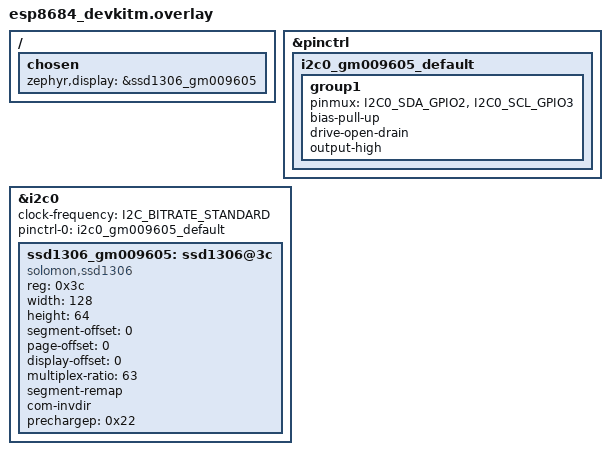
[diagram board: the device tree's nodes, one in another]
/*
 * Copyright (c) 2026 The Zephyr Project Contributors
 * Copyright (c) 2026 Espressif Systems (Shanghai) Co., Ltd.
 *
 * SPDX-License-Identifier: Apache-2.0
 *
 * GM009605 128x64 OLED (SSD1306 over I2C): SDA GPIO2, SCL GPIO3.
 */

#include <zephyr/dt-bindings/i2c/i2c.h>
#include <zephyr/dt-bindings/pinctrl/esp-pinctrl-common.h>
#include <zephyr/dt-bindings/pinctrl/esp32c2-pinctrl.h>
#include <zephyr/dt-bindings/pinctrl/esp32c2-gpio-sigmap.h>

/ {
	chosen {
		zephyr,display = &ssd1306_gm009605;
	};
};

&pinctrl {
	i2c0_gm009605_default: i2c0_gm009605_default {
		group1 {
			pinmux = <I2C0_SDA_GPIO2>,
				 <I2C0_SCL_GPIO3>;
			bias-pull-up;
			drive-open-drain;
			output-high;
		};
	};
};

&i2c0 {
	status = "okay";
	clock-frequency = <I2C_BITRATE_STANDARD>;
	pinctrl-0 = <&i2c0_gm009605_default>;
	pinctrl-names = "default";

	ssd1306_gm009605: ssd1306@3c {
		compatible = "solomon,ssd1306";
		reg = <0x3c>;
		width = <128>;
		height = <64>;
		segment-offset = <0>;
		page-offset = <0>;
		display-offset = <0>;
		multiplex-ratio = <63>;
		segment-remap;
		com-invdir;
		prechargep = <0x22>;
	};
};
